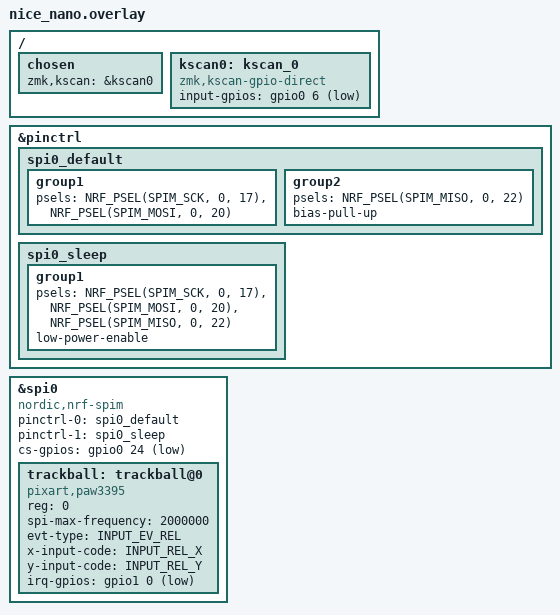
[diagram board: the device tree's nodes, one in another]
#include <dt-bindings/zmk/matrix_transform.h>
#include <dt-bindings/gpio/nordic-nrf-gpio.h>
#include <dt-bindings/input/input-event-codes.h>

/ {
    chosen {
        zmk,kscan = &kscan0;
    };

    // ВАЖНО: Изменили пин с &gpio0 0 на &gpio0 6 (на плате это D1).
    // Пин P0.00 трогать нельзя, он жестко зарезервирован под кварц Bluetooth!
    kscan0: kscan_0 {
        compatible = "zmk,kscan-gpio-direct";
        input-gpios = <&gpio0 6 (GPIO_ACTIVE_LOW | GPIO_PULL_UP)>;
    };
};

&pinctrl {
    spi0_default: spi0_default {
        group1 {
            psels = <NRF_PSEL(SPIM_SCK, 0, 17)>, 
                    <NRF_PSEL(SPIM_MOSI, 0, 20)>;
        };
        // Выносим MISO в отдельную группу, чтобы включить внутреннюю подтяжку
        group2 {
            psels = <NRF_PSEL(SPIM_MISO, 0, 22)>;
            bias-pull-up; 
        };
    };
    spi0_sleep: spi0_sleep {
        group1 {
            psels = <NRF_PSEL(SPIM_SCK, 0, 17)>,
                    <NRF_PSEL(SPIM_MOSI, 0, 20)>,
                    <NRF_PSEL(SPIM_MISO, 0, 22)>;
            low-power-enable;
        };
    };
};

&spi0 {
    status = "okay";
    compatible = "nordic,nrf-spim";
    pinctrl-0 = <&spi0_default>;
    pinctrl-1 = <&spi0_sleep>;
    pinctrl-names = "default", "sleep";
    
    cs-gpios = <&gpio0 24 GPIO_ACTIVE_LOW>; 

    trackball: trackball@0 {
        status = "okay";
        compatible = "pixart,paw3395";
        reg = <0>;
        spi-max-frequency = <2000000>;
        
        /* Параметры направления осей для драйвера badjeff */
        evt-type = <INPUT_EV_REL>;
        x-input-code = <INPUT_REL_X>;
        y-input-code = <INPUT_REL_Y>;
        
        /* Пин 100 на шелкографии — это GPIO порт 1, пин 0 */
        irq-gpios = <&gpio1 0 (GPIO_ACTIVE_LOW | GPIO_PULL_UP)>; 
    };
};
